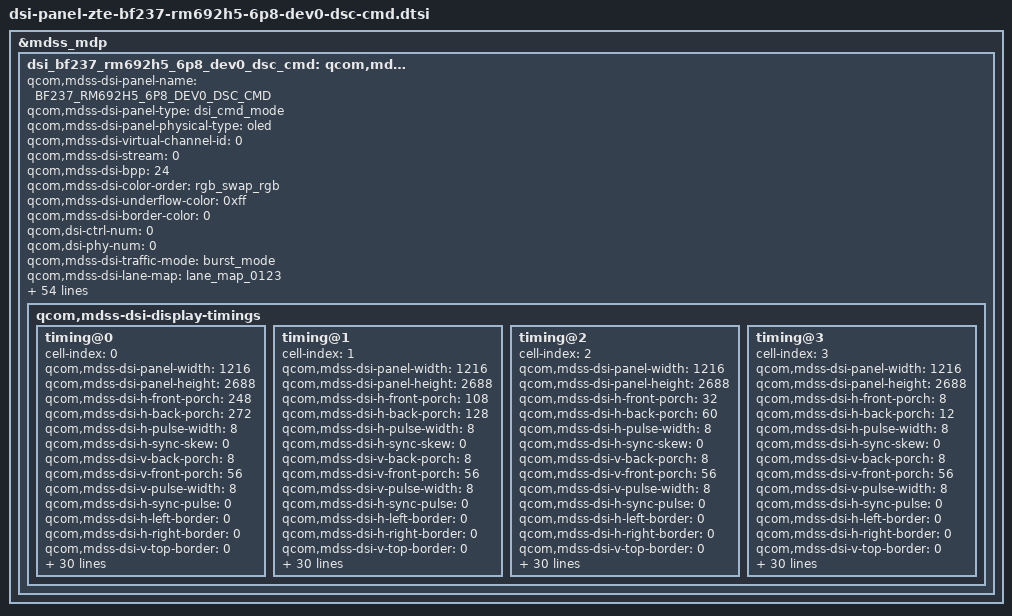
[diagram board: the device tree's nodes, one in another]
// SPDX-License-Identifier: BSD-3-Clause
/*
 * Copyright (c) 2023-2024 Qualcomm Innovation Center, Inc. All rights reserved.
 */

&mdss_mdp {
	dsi_bf237_rm692h5_6p8_dev0_dsc_cmd: qcom,mdss_dsi_bf237_rm692h5_6p8_dev0_dsc_cmd {
		qcom,mdss-dsi-panel-name =
				"BF237_RM692H5_6P8_DEV0_DSC_CMD";
		qcom,mdss-dsi-panel-type = "dsi_cmd_mode";
		qcom,mdss-dsi-panel-physical-type = "oled";
		qcom,mdss-dsi-virtual-channel-id = <0>;
		qcom,mdss-dsi-stream = <0>;
		qcom,mdss-dsi-bpp = <24>;
		qcom,mdss-dsi-color-order = "rgb_swap_rgb";
		qcom,mdss-dsi-underflow-color = <0xff>;
		qcom,mdss-dsi-border-color = <0>;
		qcom,dsi-ctrl-num = <0>;
		qcom,dsi-phy-num = <0>;
		qcom,mdss-dsi-traffic-mode = "burst_mode";
		qcom,mdss-dsi-lane-map = "lane_map_0123";
		qcom,mdss-dsi-bllp-eof-power-mode;
		qcom,mdss-dsi-bllp-power-mode;
		qcom,mdss-dsi-lane-0-state;
		qcom,mdss-dsi-lane-1-state;
		qcom,mdss-dsi-lane-2-state;
		qcom,mdss-dsi-lane-3-state;
		qcom,mdss-dsi-lp11-init;
		qcom,mdss-dsi-tx-eot-append;
		qcom,mdss-dsi-dma-trigger = "trigger_sw";
		qcom,mdss-dsi-mdp-trigger = "none";
		qcom,mdss-dsi-reset-sequence = <1 10>, <0 10>, <1 40>;
		qcom,mdss-dsi-te-pin-select = <1>;
		qcom,mdss-dsi-te-dcs-command = <1>;
		qcom,mdss-dsi-te-check-enable;
		qcom,mdss-dsi-te-using-te-pin;
		qcom,mdss-dsi-bl-min-level = <1>;
		qcom,mdss-dsi-bl-max-level = <4095>;
		qcom,mdss-dsi-bl-pmic-control-type = "bl_ctrl_dcs";
		qcom,mdss-dsi-panel-hdr-enabled;
		qcom,mdss-dsi-panel-hdr-color-primaries = <14500 15500 34015
			15980 13030 34670 6950 2565>;
		qcom,mdss-dsi-panel-peak-brightness = <6680000>;
		qcom,mdss-dsi-panel-blackness-level = <20>;
		qcom,mdss-pan-physical-width-dimension = <72>;
		qcom,mdss-pan-physical-height-dimension = <158>;
		qcom,bl-dcs-cmd-state = "dsi_lp_mode";
		qcom,bl-dsc-cmd-state = "dsi_lp_mode";
		qcom,mdss-disable-cesta-hw-sleep;
		qcom,mdss-dsi-display-timings {
			timing@0 {
				cell-index = <0>;
				qcom,mdss-dsi-panel-width = <1216>;
				qcom,mdss-dsi-panel-height = <2688>;
				qcom,mdss-dsi-h-front-porch = <248>;
				qcom,mdss-dsi-h-back-porch = <272>;
				qcom,mdss-dsi-h-pulse-width = <8>;
				qcom,mdss-dsi-h-sync-skew = <0>;
				qcom,mdss-dsi-v-back-porch = <8>;
				qcom,mdss-dsi-v-front-porch = <56>;
				qcom,mdss-dsi-v-pulse-width = <8>;
				qcom,mdss-dsi-h-sync-pulse = <0>;
				qcom,mdss-dsi-h-left-border = <0>;
				qcom,mdss-dsi-h-right-border = <0>;
				qcom,mdss-dsi-v-top-border = <0>;
				qcom,mdss-dsi-v-bottom-border = <0>;
				qcom,mdss-dsi-panel-framerate = <60>;
				qcom,mdss-mdp-transfer-time-us = <6235>;
				/*qcom,mdss-dsi-panel-clockrate = <1060499680>;*/
				/*qcom,mdss-dsi-panel-clockrate = <1059430000>; 60HZ*/

				qcom,mdss-dsi-on-command = [
					/* ESD RECOVER */
					15 01 00 00 00 00 02 FE D4
					15 01 00 00 00 00 02 40 03
					15 01 00 00 00 00 02 FE FD
					15 01 00 00 00 00 02 80 06
					15 01 00 00 00 00 02 83 00
					15 01 00 00 00 00 02 EE 00
					15 01 00 00 00 00 02 EF 00
					15 01 00 00 00 00 02 FE D0
					15 01 00 00 00 00 02 7E 80
					15 01 00 00 00 00 02 FE B6
					15 01 00 00 00 00 02 01 74
					15 01 00 00 00 00 02 FE A1
					15 01 00 00 00 00 02 74 72
					15 01 00 00 00 00 02 C3 C3
					15 01 00 00 00 00 02 C4 FF
					15 01 00 00 00 00 02 C5 7F
/*10bit 3.75 begin*/
15 01 00 00 00 00 02 FE 00
15 01 00 00 00 00 02 FA 01
15 01 00 00 00 00 02 FE D2
15 01 00 00 00 00 02 97 08
15 01 00 00 00 00 02 36 11
15 01 00 00 00 00 02 39 ab
15 01 00 00 00 00 02 3A 30
15 01 00 00 00 00 02 3B 80
15 01 00 00 00 00 02 3D 0a
15 01 00 00 00 00 02 3F 80
15 01 00 00 00 00 02 40 04
15 01 00 00 00 00 02 41 c0
15 01 00 00 00 00 02 42 00
15 01 00 00 00 00 02 43 10
15 01 00 00 00 00 02 44 02
15 01 00 00 00 00 02 45 60
15 01 00 00 00 00 02 46 02
15 01 00 00 00 00 02 47 60
15 01 00 00 00 00 02 48 02
15 01 00 00 00 00 02 49 00
15 01 00 00 00 00 02 4A 02
15 01 00 00 00 00 02 4B 31
15 01 00 00 00 00 02 4D 20
15 01 00 00 00 00 02 4E 01
15 01 00 00 00 00 02 4F 68
15 01 00 00 00 00 02 50 00
15 01 00 00 00 00 02 51 08
15 01 00 00 00 00 02 53 0c
15 01 00 00 00 00 02 54 06
15 01 00 00 00 00 02 55 67
15 01 00 00 00 00 02 56 05
15 01 00 00 00 00 02 58 ad
15 01 00 00 00 00 02 59 18
15 01 00 00 00 00 02 5A 00
15 01 00 00 00 00 02 5B 11
15 01 00 00 00 00 02 5C 00
15 01 00 00 00 00 02 5D 07
15 01 00 00 00 00 02 5E 10
15 01 00 00 00 00 02 5F 20
15 01 00 00 00 00 02 60 00
15 01 00 00 00 00 02 61 06
15 01 00 00 00 00 02 62 0f
15 01 00 00 00 00 02 63 0f
15 01 00 00 00 00 02 64 33
15 01 00 00 00 00 02 65 0e
15 01 00 00 00 00 02 66 1c
15 01 00 00 00 00 02 67 2a
15 01 00 00 00 00 02 68 38
15 01 00 00 00 00 02 69 46
15 01 00 00 00 00 02 6A 54
15 01 00 00 00 00 02 6B 62
15 01 00 00 00 00 02 6C 69
15 01 00 00 00 00 02 6D 70
15 01 00 00 00 00 02 6E 77
15 01 00 00 00 00 02 6F 79
15 01 00 00 00 00 02 70 7b
15 01 00 00 00 00 02 71 7d
15 01 00 00 00 00 02 72 7e
15 01 00 00 00 00 02 73 02
15 01 00 00 00 00 02 74 02
15 01 00 00 00 00 02 75 22
15 01 00 00 00 00 02 76 00
15 01 00 00 00 00 02 77 2a
15 01 00 00 00 00 02 78 40
15 01 00 00 00 00 02 79 2a
15 01 00 00 00 00 02 7A be
15 01 00 00 00 00 02 7B 3a
15 01 00 00 00 00 02 7C fc
15 01 00 00 00 00 02 7D 3a
15 01 00 00 00 00 02 7E fa
15 01 00 00 00 00 02 7F 3a
15 01 00 00 00 00 02 80 f8
15 01 00 00 00 00 02 81 3b
15 01 00 00 00 00 02 82 38
15 01 00 00 00 00 02 83 3b
15 01 00 00 00 00 02 84 78
15 01 00 00 00 00 02 85 3b
15 01 00 00 00 00 02 86 b6
15 01 00 00 00 00 02 87 4b
15 01 00 00 00 00 02 88 f6
15 01 00 00 00 00 02 89 4c
15 01 00 00 00 00 02 8A 34
15 01 00 00 00 00 02 8B 4c
15 01 00 00 00 00 02 8C 74
15 01 00 00 00 00 02 8D 5c
15 01 00 00 00 00 02 8E 74
15 01 00 00 00 00 02 8F 8c
15 01 00 00 00 00 02 90 f4
15 01 00 00 00 00 02 91 00
15 01 00 00 00 00 02 92 00
15 01 00 00 00 00 02 93 00
15 01 00 00 00 00 02 94 00
15 01 00 00 00 00 02 95 00
15 01 00 00 00 00 02 96 00
/*10bit 3.75 end*/

/*acl function*/
15 01 00 00 00 00 02 FE 34
15 01 00 00 00 00 02 82 C0
15 01 00 00 00 00 02 83 04
15 01 00 00 00 00 02 00 08
15 01 00 00 00 00 02 1C 00
15 01 00 00 00 00 02 1D 10
15 01 00 00 00 00 02 49 05
15 01 00 00 00 00 02 1E 00
15 01 00 00 00 00 02 1F 00
15 01 00 00 00 00 02 20 00
15 01 00 00 00 00 02 21 70
15 01 00 00 00 00 02 22 00
15 01 00 00 00 00 02 23 F8
15 01 00 00 00 00 02 24 77
15 01 00 00 00 00 02 25 F8
15 01 00 00 00 00 02 26 F8
15 01 00 00 00 00 02 2F 00
15 01 00 00 00 00 02 30 00
15 01 00 00 00 00 02 31 00
15 01 00 00 00 00 02 32 00
15 01 00 00 00 00 02 33 00
15 01 00 00 00 00 02 34 00
15 01 00 00 00 00 02 35 00
15 01 00 00 00 00 02 36 C4
15 01 00 00 00 00 02 37 00
15 01 00 00 00 00 02 38 87
15 01 00 00 00 00 02 39 00
15 01 00 00 00 00 02 3A 4B
15 01 00 00 00 00 02 3B 00
15 01 00 00 00 00 02 3D 00
15 01 00 00 00 00 02 3F 00
15 01 00 00 00 00 02 40 00
15 01 00 00 00 00 02 41 00
15 01 00 00 00 00 02 42 00
15 01 00 00 00 00 02 54 03
15 01 00 00 00 00 02 55 77
15 01 00 00 00 00 02 56 F8
15 01 00 00 00 00 02 58 F8
15 01 00 00 00 00 02 59 77
15 01 00 00 00 00 02 5A F8
15 01 00 00 00 00 02 5B F8
15 01 00 00 00 00 02 5C 77
15 01 00 00 00 00 02 5D F8
15 01 00 00 00 00 02 5E F8
15 01 00 00 00 00 02 5F 77
15 01 00 00 00 00 02 60 F8
15 01 00 00 00 00 02 61 F8
15 01 00 00 00 00 02 62 77
15 01 00 00 00 00 02 63 F8
15 01 00 00 00 00 02 64 F8
15 01 00 00 00 00 02 65 77
15 01 00 00 00 00 02 66 F8
15 01 00 00 00 00 02 67 F8
15 01 00 00 00 00 02 77 07
15 01 00 00 00 00 02 78 F8
/*FDC effect*/
15 01 00 00 00 00 02 FE 00
15 01 00 00 00 00 02 2F 07
15 01 00 00 00 00 02 FE 5A
15 01 00 00 00 00 02 4A 1A
15 01 00 00 00 00 02 4B 00
15 01 00 00 00 00 02 52 00
15 01 00 00 00 00 02 53 08
15 01 00 00 00 00 02 55 00
15 01 00 00 00 00 02 5E 00
15 01 00 00 00 00 02 60 04
15 01 00 00 00 00 02 61 04
15 01 00 00 00 00 02 66 00
15 01 00 00 00 00 02 69 00
15 01 00 00 00 00 02 6E 00
15 01 00 00 00 00 02 70 00
15 01 00 00 00 00 02 76 00
15 01 00 00 00 00 02 78 00
15 01 00 00 00 00 02 7E 00
15 01 00 00 00 00 02 86 00
15 01 00 00 00 00 02 91 10
15 01 00 00 00 00 02 92 00
15 01 00 00 00 00 02 93 10
15 01 00 00 00 00 02 94 06
15 01 00 00 00 00 02 98 00
15 01 00 00 00 00 02 99 00
15 01 00 00 00 00 02 9B 00
15 01 00 00 00 00 02 9C 00
15 01 00 00 00 00 02 A2 00
15 01 00 00 00 00 02 A7 00
15 01 00 00 00 00 02 AA 00
15 01 00 00 00 00 02 AB 00
15 01 00 00 00 00 02 B0 00
15 01 00 00 00 00 02 B3 00
15 01 00 00 00 00 02 B8 00
15 01 00 00 00 00 02 BA 00
15 01 00 00 00 00 02 C0 00
15 01 00 00 00 00 02 C8 00
15 01 00 00 00 00 02 D0 00
15 01 00 00 00 00 02 DB 30
15 01 00 00 00 00 02 DC 3D
15 01 00 00 00 00 02 DD 20
15 01 00 00 00 00 02 DE 00
15 01 00 00 00 00 02 E2 30
15 01 00 00 00 00 02 E3 30
15 01 00 00 00 00 02 E4 20
15 01 00 00 00 00 02 E5 00
15 01 00 00 00 00 02 E6 00
15 01 00 00 00 00 02 EA 10
15 01 00 00 00 00 02 EB 1A
15 01 00 00 00 00 02 F0 00
15 01 00 00 00 00 02 F3 0D
15 01 00 00 00 00 02 F4 02
15 01 00 00 00 00 02 F9 00
15 01 00 00 00 00 02 FE 5B
15 01 00 00 00 00 02 01 0D
15 01 00 00 00 00 02 02 0A
15 01 00 00 00 00 02 07 00
15 01 00 00 00 00 02 09 06
15 01 00 00 00 00 02 0F 00
15 01 00 00 00 00 02 11 06
15 01 00 00 00 00 02 19 00
15 01 00 00 00 00 02 36 00
15 01 00 00 00 00 02 37 00
15 01 00 00 00 00 02 3F 00
15 01 00 00 00 00 02 45 F9
15 01 00 00 00 00 02 46 00
15 01 00 00 00 00 02 47 00
15 01 00 00 00 00 02 4D F9
15 01 00 00 00 00 02 55 FB
15 01 00 00 00 00 02 56 FF
15 01 00 00 00 00 02 5E FC
					/* init code */
					15 01 00 00 00 00 02 FE 00
					15 01 00 00 00 00 02 C2 08
					15 01 00 00 00 00 02 35 00
					15 01 00 00 00 00 02 53 20
					39 01 00 00 00 00 03 51 00 00
					05 01 00 00 64 00 01 11
					05 01 00 00 14 00 01 29
					];
				qcom,mdss-dsi-off-command = [
					15 01 00 00 14 00 02 FE 00
					05 01 00 00 10 00 01 28
					05 01 00 00 78 00 01 10
				];
				qcom,mdss-dsi-on-command-state = "dsi_lp_mode";
				qcom,mdss-dsi-off-command-state = "dsi_lp_mode";

				qcom,mdss-dsi-lp1-command = [
					15 01 00 00 00 00 02 FE 00
					05 01 00 00 14 00 01 39
				];
				qcom,mdss-dsi-lp1-command-state =
					"dsi_lp_mode";
				qcom,mdss-dsi-nolp-command = [
					15 01 00 00 00 00 02 FE 00
					39 01 00 00 00 00 03 51 00 00
					05 01 00 00 00 00 01 38
				];
				qcom,mdss-dsi-nolp-command-state =
					"dsi_lp_mode";
				qcom,mdss-dsi-timing-switch-command = [
39 00 00 40 00 00 02 FE 00
39 00 00 40 00 00 02 2F 07

39 00 00 40 00 00 02 FE 5A
39 00 00 40 00 00 02 4A 1A
39 00 00 40 00 00 02 4B 00
39 00 00 40 00 00 02 52 00
39 00 00 40 00 00 02 53 08
39 00 00 40 00 00 02 55 00
39 00 00 40 00 00 02 5E 00
39 00 00 40 00 00 02 60 04
39 00 00 40 00 00 02 61 04
39 00 00 40 00 00 02 66 00
39 00 00 40 00 00 02 69 00
39 00 00 40 00 00 02 6E 00
39 00 00 40 00 00 02 70 00
39 00 00 40 00 00 02 76 00
39 00 00 40 00 00 02 78 00
39 00 00 40 00 00 02 7E 00
39 00 00 40 00 00 02 86 00
39 00 00 40 00 00 02 91 10
39 00 00 40 00 00 02 92 00
39 00 00 40 00 00 02 93 10
39 00 00 40 00 00 02 94 06
39 00 00 40 00 00 02 98 00
39 00 00 40 00 00 02 99 00
39 00 00 40 00 00 02 9B 00
39 00 00 40 00 00 02 9C 00
39 00 00 40 00 00 02 A2 00
39 00 00 40 00 00 02 A7 00
39 00 00 40 00 00 02 AA 00
39 00 00 40 00 00 02 AB 00
39 00 00 40 00 00 02 B0 00
39 00 00 40 00 00 02 B3 00
39 00 00 40 00 00 02 B8 00
39 00 00 40 00 00 02 BA 00
39 00 00 40 00 00 02 C0 00
39 00 00 40 00 00 02 C8 00
39 00 00 40 00 00 02 D0 00
39 00 00 40 00 00 02 DB 30
39 00 00 40 00 00 02 DC 3D
39 00 00 40 00 00 02 DD 20
39 00 00 40 00 00 02 DE 00
39 00 00 40 00 00 02 E2 30
39 00 00 40 00 00 02 E3 30
39 00 00 40 00 00 02 E4 20
39 00 00 40 00 00 02 E5 00
39 00 00 40 00 00 02 E6 00
39 00 00 40 00 00 02 EA 10
39 00 00 40 00 00 02 EB 1A
39 00 00 40 00 00 02 F0 00
39 00 00 40 00 00 02 F3 0D
39 00 00 40 00 00 02 F4 02
39 00 00 40 00 00 02 F9 00
39 00 00 40 00 00 02 FE 5B
39 00 00 40 00 00 02 01 0D
39 00 00 40 00 00 02 02 0A
39 00 00 40 00 00 02 07 00
39 00 00 40 00 00 02 09 06
39 00 00 40 00 00 02 0F 00
39 00 00 40 00 00 02 11 06
39 00 00 40 00 00 02 19 00
39 00 00 40 00 00 02 36 00
39 00 00 40 00 00 02 37 00
39 00 00 40 00 00 02 3F 00
39 00 00 40 00 00 02 45 F9
39 00 00 40 00 00 02 46 00
39 00 00 40 00 00 02 47 00
39 00 00 40 00 00 02 4D F9
39 00 00 40 00 00 02 55 FB
39 00 00 40 00 00 02 56 FF
39 00 00 40 00 00 02 5E FC
					39 00 00 00 00 00 02 FE 00
				];
				qcom,mdss-dsi-timing-switch-command-state =
				"dsi_lp_mode";
				qcom,compression-mode = "dsc";
				qcom,mdss-dsc-slice-height = <16>;
				qcom,mdss-dsc-slice-width = <608>;
				qcom,mdss-dsc-slice-per-pkt = <2>;
				qcom,mdss-dsc-bit-per-component = <10>;
				qcom,mdss-dsc-bit-per-pixel = <8>;
				qcom,mdss-dsc-block-prediction-enable;
			};
			timing@1{
				cell-index = <1>;
				qcom,mdss-dsi-panel-width = <1216>;
				qcom,mdss-dsi-panel-height = <2688>;
				qcom,mdss-dsi-h-front-porch = <108>;
				qcom,mdss-dsi-h-back-porch = <128>;
				qcom,mdss-dsi-h-pulse-width = <8>;
				qcom,mdss-dsi-h-sync-skew = <0>;
				qcom,mdss-dsi-v-back-porch = <8>;
				qcom,mdss-dsi-v-front-porch = <56>;
				qcom,mdss-dsi-v-pulse-width = <8>;
				qcom,mdss-dsi-h-sync-pulse = <0>;
				qcom,mdss-dsi-h-left-border = <0>;
				qcom,mdss-dsi-h-right-border = <0>;
				qcom,mdss-dsi-v-top-border = <0>;
				qcom,mdss-dsi-v-bottom-border = <0>;
				qcom,mdss-dsi-panel-framerate = <90>;
				qcom,mdss-mdp-transfer-time-us = <6235>;
				/*qcom,mdss-dsi-panel-clockrate = <1060531504>;*/
				/*qcom,mdss-dsi-panel-clockrate = <1060050000>; 90HZ*/

				qcom,mdss-dsi-on-command = [
					/* ESD RECOVER */
					15 01 00 00 00 00 02 FE D4
					15 01 00 00 00 00 02 40 03
					15 01 00 00 00 00 02 FE FD
					15 01 00 00 00 00 02 80 06
					15 01 00 00 00 00 02 83 00
					15 01 00 00 00 00 02 EE 00
					15 01 00 00 00 00 02 EF 00
					15 01 00 00 00 00 02 FE D0
					15 01 00 00 00 00 02 7E 80
					15 01 00 00 00 00 02 FE B6
					15 01 00 00 00 00 02 01 74
					15 01 00 00 00 00 02 FE A1
					15 01 00 00 00 00 02 74 72
					15 01 00 00 00 00 02 C3 C3
					15 01 00 00 00 00 02 C4 FF
					15 01 00 00 00 00 02 C5 7F
/*10bit 3.75 begin*/
15 01 00 00 00 00 02 FE 00
15 01 00 00 00 00 02 FA 01
15 01 00 00 00 00 02 FE D2
15 01 00 00 00 00 02 97 08
15 01 00 00 00 00 02 36 11
15 01 00 00 00 00 02 39 ab
15 01 00 00 00 00 02 3A 30
15 01 00 00 00 00 02 3B 80
15 01 00 00 00 00 02 3D 0a
15 01 00 00 00 00 02 3F 80
15 01 00 00 00 00 02 40 04
15 01 00 00 00 00 02 41 c0
15 01 00 00 00 00 02 42 00
15 01 00 00 00 00 02 43 10
15 01 00 00 00 00 02 44 02
15 01 00 00 00 00 02 45 60
15 01 00 00 00 00 02 46 02
15 01 00 00 00 00 02 47 60
15 01 00 00 00 00 02 48 02
15 01 00 00 00 00 02 49 00
15 01 00 00 00 00 02 4A 02
15 01 00 00 00 00 02 4B 31
15 01 00 00 00 00 02 4D 20
15 01 00 00 00 00 02 4E 01
15 01 00 00 00 00 02 4F 68
15 01 00 00 00 00 02 50 00
15 01 00 00 00 00 02 51 08
15 01 00 00 00 00 02 53 0c
15 01 00 00 00 00 02 54 06
15 01 00 00 00 00 02 55 67
15 01 00 00 00 00 02 56 05
15 01 00 00 00 00 02 58 ad
15 01 00 00 00 00 02 59 18
15 01 00 00 00 00 02 5A 00
15 01 00 00 00 00 02 5B 11
15 01 00 00 00 00 02 5C 00
15 01 00 00 00 00 02 5D 07
15 01 00 00 00 00 02 5E 10
15 01 00 00 00 00 02 5F 20
15 01 00 00 00 00 02 60 00
15 01 00 00 00 00 02 61 06
15 01 00 00 00 00 02 62 0f
15 01 00 00 00 00 02 63 0f
15 01 00 00 00 00 02 64 33
15 01 00 00 00 00 02 65 0e
15 01 00 00 00 00 02 66 1c
15 01 00 00 00 00 02 67 2a
15 01 00 00 00 00 02 68 38
15 01 00 00 00 00 02 69 46
15 01 00 00 00 00 02 6A 54
15 01 00 00 00 00 02 6B 62
15 01 00 00 00 00 02 6C 69
15 01 00 00 00 00 02 6D 70
15 01 00 00 00 00 02 6E 77
15 01 00 00 00 00 02 6F 79
15 01 00 00 00 00 02 70 7b
15 01 00 00 00 00 02 71 7d
15 01 00 00 00 00 02 72 7e
15 01 00 00 00 00 02 73 02
15 01 00 00 00 00 02 74 02
15 01 00 00 00 00 02 75 22
15 01 00 00 00 00 02 76 00
15 01 00 00 00 00 02 77 2a
15 01 00 00 00 00 02 78 40
15 01 00 00 00 00 02 79 2a
15 01 00 00 00 00 02 7A be
15 01 00 00 00 00 02 7B 3a
15 01 00 00 00 00 02 7C fc
15 01 00 00 00 00 02 7D 3a
15 01 00 00 00 00 02 7E fa
15 01 00 00 00 00 02 7F 3a
15 01 00 00 00 00 02 80 f8
15 01 00 00 00 00 02 81 3b
15 01 00 00 00 00 02 82 38
15 01 00 00 00 00 02 83 3b
15 01 00 00 00 00 02 84 78
15 01 00 00 00 00 02 85 3b
15 01 00 00 00 00 02 86 b6
15 01 00 00 00 00 02 87 4b
15 01 00 00 00 00 02 88 f6
15 01 00 00 00 00 02 89 4c
15 01 00 00 00 00 02 8A 34
15 01 00 00 00 00 02 8B 4c
15 01 00 00 00 00 02 8C 74
15 01 00 00 00 00 02 8D 5c
15 01 00 00 00 00 02 8E 74
15 01 00 00 00 00 02 8F 8c
15 01 00 00 00 00 02 90 f4
15 01 00 00 00 00 02 91 00
15 01 00 00 00 00 02 92 00
15 01 00 00 00 00 02 93 00
15 01 00 00 00 00 02 94 00
15 01 00 00 00 00 02 95 00
15 01 00 00 00 00 02 96 00
/*10bit 3.75 end*/
/*acl function*/
15 01 00 00 00 00 02 FE 34
15 01 00 00 00 00 02 82 C0
15 01 00 00 00 00 02 83 04
15 01 00 00 00 00 02 00 08
15 01 00 00 00 00 02 1C 00
15 01 00 00 00 00 02 1D 10
15 01 00 00 00 00 02 49 05
15 01 00 00 00 00 02 1E 00
15 01 00 00 00 00 02 1F 00
15 01 00 00 00 00 02 20 00
15 01 00 00 00 00 02 21 70
15 01 00 00 00 00 02 22 00
15 01 00 00 00 00 02 23 F8
15 01 00 00 00 00 02 24 77
15 01 00 00 00 00 02 25 F8
15 01 00 00 00 00 02 26 F8
15 01 00 00 00 00 02 2F 00
15 01 00 00 00 00 02 30 00
15 01 00 00 00 00 02 31 00
15 01 00 00 00 00 02 32 00
15 01 00 00 00 00 02 33 00
15 01 00 00 00 00 02 34 00
15 01 00 00 00 00 02 35 00
15 01 00 00 00 00 02 36 C4
15 01 00 00 00 00 02 37 00
15 01 00 00 00 00 02 38 87
15 01 00 00 00 00 02 39 00
15 01 00 00 00 00 02 3A 4B
15 01 00 00 00 00 02 3B 00
15 01 00 00 00 00 02 3D 00
15 01 00 00 00 00 02 3F 00
15 01 00 00 00 00 02 40 00
15 01 00 00 00 00 02 41 00
15 01 00 00 00 00 02 42 00
15 01 00 00 00 00 02 54 03
15 01 00 00 00 00 02 55 77
15 01 00 00 00 00 02 56 F8
15 01 00 00 00 00 02 58 F8
15 01 00 00 00 00 02 59 77
15 01 00 00 00 00 02 5A F8
15 01 00 00 00 00 02 5B F8
15 01 00 00 00 00 02 5C 77
15 01 00 00 00 00 02 5D F8
15 01 00 00 00 00 02 5E F8
15 01 00 00 00 00 02 5F 77
15 01 00 00 00 00 02 60 F8
15 01 00 00 00 00 02 61 F8
15 01 00 00 00 00 02 62 77
15 01 00 00 00 00 02 63 F8
15 01 00 00 00 00 02 64 F8
15 01 00 00 00 00 02 65 77
15 01 00 00 00 00 02 66 F8
15 01 00 00 00 00 02 67 F8
15 01 00 00 00 00 02 77 07
15 01 00 00 00 00 02 78 F8
/* FDC */
15 01 00 00 00 00 02 FE 00
15 01 00 00 00 00 02 2F 06
15 01 00 00 00 00 02 FE 5A
15 01 00 00 00 00 02 4A 00
15 01 00 00 00 00 02 4B 00
15 01 00 00 00 00 02 52 00
15 01 00 00 00 00 02 53 00
15 01 00 00 00 00 02 55 00
15 01 00 00 00 00 02 60 00
15 01 00 00 00 00 02 61 00
15 01 00 00 00 00 02 66 00
15 01 00 00 00 00 02 6E 00
15 01 00 00 00 00 02 70 00
15 01 00 00 00 00 02 76 00
15 01 00 00 00 00 02 7E 00
15 01 00 00 00 00 02 86 00
15 01 00 00 00 00 02 91 12
15 01 00 00 00 00 02 92 0A
15 01 00 00 00 00 02 93 00
15 01 00 00 00 00 02 94 00
15 01 00 00 00 00 02 98 10
15 01 00 00 00 00 02 99 06
15 01 00 00 00 00 02 9B 00
15 01 00 00 00 00 02 9C 00
15 01 00 00 00 00 02 AB 00
15 01 00 00 00 00 02 B0 00
15 01 00 00 00 00 02 B8 00
15 01 00 00 00 00 02 BA 00
15 01 00 00 00 00 02 C0 00
15 01 00 00 00 00 02 C8 00
15 01 00 00 00 00 02 D0 00
15 01 00 00 00 00 02 DB 66
15 01 00 00 00 00 02 DC 5A
15 01 00 00 00 00 02 DD 26
15 01 00 00 00 00 02 DE 00
15 01 00 00 00 00 02 E2 55
15 01 00 00 00 00 02 E3 2E
15 01 00 00 00 00 02 E4 36
15 01 00 00 00 00 02 E5 00
15 01 00 00 00 00 02 E6 00
15 01 00 00 00 00 02 EA 20
15 01 00 00 00 00 02 EB 14
15 01 00 00 00 00 02 F3 15
15 01 00 00 00 00 02 F4 12
15 01 00 00 00 00 02 F9 00
15 01 00 00 00 00 02 FE 5B
15 01 00 00 00 00 02 01 12
15 01 00 00 00 00 02 02 12
15 01 00 00 00 00 02 07 00
15 01 00 00 00 00 02 09 08
15 01 00 00 00 00 02 0F 00
15 01 00 00 00 00 02 11 0A
15 01 00 00 00 00 02 19 06
15 01 00 00 00 00 02 36 10
15 01 00 00 00 00 02 37 00
15 01 00 00 00 00 02 3F 00
15 01 00 00 00 00 02 45 FE
15 01 00 00 00 00 02 46 00
15 01 00 00 00 00 02 47 00
15 01 00 00 00 00 02 4D FA
15 01 00 00 00 00 02 55 00
15 01 00 00 00 00 02 56 00
15 01 00 00 00 00 02 5E 00
					/* init code */
					15 01 00 00 00 00 02 FE 00
					15 01 00 00 00 00 02 C2 08
					15 01 00 00 00 00 02 35 00
					15 01 00 00 00 00 02 53 20
					39 01 00 00 00 00 03 51 00 00
					05 01 00 00 64 00 01 11
					05 01 00 00 14 00 01 29
					];
				qcom,mdss-dsi-off-command = [
					15 01 00 00 14 00 02 FE 00
					05 01 00 00 10 00 01 28
					05 01 00 00 78 00 01 10
				];
				qcom,mdss-dsi-on-command-state = "dsi_lp_mode";
				qcom,mdss-dsi-off-command-state = "dsi_lp_mode";

				qcom,mdss-dsi-lp1-command = [
					15 01 00 00 00 00 02 FE 00
					05 01 00 00 14 00 01 39
				];
				qcom,mdss-dsi-lp1-command-state =
					"dsi_lp_mode";
				qcom,mdss-dsi-nolp-command = [
					15 01 00 00 00 00 02 FE 00
					39 01 00 00 00 00 03 51 00 00
					05 01 00 00 00 00 01 38
				];
				qcom,mdss-dsi-nolp-command-state =
					"dsi_lp_mode";
				qcom,mdss-dsi-timing-switch-command = [
39 00 00 40 00 00 02 FE 00
39 00 00 40 00 00 02 2F 06

39 00 00 40 00 00 02 FE 5A
39 00 00 40 00 00 02 4A 00
39 00 00 40 00 00 02 4B 00
39 00 00 40 00 00 02 52 00
39 00 00 40 00 00 02 53 00
39 00 00 40 00 00 02 55 00
39 00 00 40 00 00 02 60 00
39 00 00 40 00 00 02 61 00
39 00 00 40 00 00 02 66 00
39 00 00 40 00 00 02 6E 00
39 00 00 40 00 00 02 70 00
39 00 00 40 00 00 02 76 00
39 00 00 40 00 00 02 7E 00
39 00 00 40 00 00 02 86 00
39 00 00 40 00 00 02 91 12
39 00 00 40 00 00 02 92 0A
39 00 00 40 00 00 02 93 00
39 00 00 40 00 00 02 94 00
39 00 00 40 00 00 02 98 10
39 00 00 40 00 00 02 99 06
39 00 00 40 00 00 02 9B 00
39 00 00 40 00 00 02 9C 00
39 00 00 40 00 00 02 AB 00
39 00 00 40 00 00 02 B0 00
39 00 00 40 00 00 02 B8 00
39 00 00 40 00 00 02 BA 00
39 00 00 40 00 00 02 C0 00
39 00 00 40 00 00 02 C8 00
39 00 00 40 00 00 02 D0 00
39 00 00 40 00 00 02 DB 66
39 00 00 40 00 00 02 DC 5A
39 00 00 40 00 00 02 DD 26
39 00 00 40 00 00 02 DE 00
39 00 00 40 00 00 02 E2 55
39 00 00 40 00 00 02 E3 2E
39 00 00 40 00 00 02 E4 36
39 00 00 40 00 00 02 E5 00
39 00 00 40 00 00 02 E6 00
39 00 00 40 00 00 02 EA 20
39 00 00 40 00 00 02 EB 14
39 00 00 40 00 00 02 F3 15
39 00 00 40 00 00 02 F4 12
39 00 00 40 00 00 02 F9 00
39 00 00 40 00 00 02 FE 5B
39 00 00 40 00 00 02 01 12
39 00 00 40 00 00 02 02 12
39 00 00 40 00 00 02 07 00
39 00 00 40 00 00 02 09 08
39 00 00 40 00 00 02 0F 00
39 00 00 40 00 00 02 11 0A
39 00 00 40 00 00 02 19 06
39 00 00 40 00 00 02 36 10
39 00 00 40 00 00 02 37 00
39 00 00 40 00 00 02 3F 00
39 00 00 40 00 00 02 45 FE
39 00 00 40 00 00 02 46 00
39 00 00 40 00 00 02 47 00
39 00 00 40 00 00 02 4D FA
39 00 00 40 00 00 02 55 00
39 00 00 40 00 00 02 56 00
39 00 00 40 00 00 02 5E 00
					39 00 00 00 00 00 02 FE 00
				];
				qcom,mdss-dsi-timing-switch-command-state =
				"dsi_lp_mode";
				qcom,compression-mode = "dsc";
				qcom,mdss-dsc-slice-height = <16>;
				qcom,mdss-dsc-slice-width = <608>;
				qcom,mdss-dsc-slice-per-pkt = <2>;
				qcom,mdss-dsc-bit-per-component = <10>;
				qcom,mdss-dsc-bit-per-pixel = <8>;
				qcom,mdss-dsc-block-prediction-enable;
			};
			timing@2{
				cell-index = <2>;
				qcom,mdss-dsi-panel-width = <1216>;
				qcom,mdss-dsi-panel-height = <2688>;
				qcom,mdss-dsi-h-front-porch = <32>;
				qcom,mdss-dsi-h-back-porch = <60>;
				qcom,mdss-dsi-h-pulse-width = <8>;
				qcom,mdss-dsi-h-sync-skew = <0>;
				qcom,mdss-dsi-v-back-porch = <8>;
				qcom,mdss-dsi-v-front-porch = <56>;
				qcom,mdss-dsi-v-pulse-width = <8>;
				qcom,mdss-dsi-h-sync-pulse = <0>;
				qcom,mdss-dsi-h-left-border = <0>;
				qcom,mdss-dsi-h-right-border = <0>;
				qcom,mdss-dsi-v-top-border = <0>;
				qcom,mdss-dsi-v-bottom-border = <0>;
				qcom,mdss-dsi-panel-framerate = <120>;
				qcom,mdss-mdp-transfer-time-us = <6235>;
				/*qcom,mdss-dsi-panel-clockrate = <1060499680>;*/
				/*qcom,mdss-dsi-panel-clockrate = <1055700000>; 120HZ*/

				qcom,mdss-dsi-on-command = [
					/* ESD RECOVER */
					15 01 00 00 00 00 02 FE D4
					15 01 00 00 00 00 02 40 03
					15 01 00 00 00 00 02 FE FD
					15 01 00 00 00 00 02 80 06
					15 01 00 00 00 00 02 83 00
					15 01 00 00 00 00 02 EE 00
					15 01 00 00 00 00 02 EF 00
					15 01 00 00 00 00 02 FE D0
					15 01 00 00 00 00 02 7E 80
					15 01 00 00 00 00 02 FE B6
					15 01 00 00 00 00 02 01 74
					15 01 00 00 00 00 02 FE A1
					15 01 00 00 00 00 02 74 72
					15 01 00 00 00 00 02 C3 C3
					15 01 00 00 00 00 02 C4 FF
					15 01 00 00 00 00 02 C5 7F
/*10bit 3.75 begin*/
15 01 00 00 00 00 02 FE 00
15 01 00 00 00 00 02 FA 01
15 01 00 00 00 00 02 FE D2
15 01 00 00 00 00 02 97 08
15 01 00 00 00 00 02 36 11
15 01 00 00 00 00 02 39 ab
15 01 00 00 00 00 02 3A 30
15 01 00 00 00 00 02 3B 80
15 01 00 00 00 00 02 3D 0a
15 01 00 00 00 00 02 3F 80
15 01 00 00 00 00 02 40 04
15 01 00 00 00 00 02 41 c0
15 01 00 00 00 00 02 42 00
15 01 00 00 00 00 02 43 10
15 01 00 00 00 00 02 44 02
15 01 00 00 00 00 02 45 60
15 01 00 00 00 00 02 46 02
15 01 00 00 00 00 02 47 60
15 01 00 00 00 00 02 48 02
15 01 00 00 00 00 02 49 00
15 01 00 00 00 00 02 4A 02
15 01 00 00 00 00 02 4B 31
15 01 00 00 00 00 02 4D 20
15 01 00 00 00 00 02 4E 01
15 01 00 00 00 00 02 4F 68
15 01 00 00 00 00 02 50 00
15 01 00 00 00 00 02 51 08
15 01 00 00 00 00 02 53 0c
15 01 00 00 00 00 02 54 06
15 01 00 00 00 00 02 55 67
15 01 00 00 00 00 02 56 05
15 01 00 00 00 00 02 58 ad
15 01 00 00 00 00 02 59 18
15 01 00 00 00 00 02 5A 00
15 01 00 00 00 00 02 5B 11
15 01 00 00 00 00 02 5C 00
15 01 00 00 00 00 02 5D 07
15 01 00 00 00 00 02 5E 10
15 01 00 00 00 00 02 5F 20
15 01 00 00 00 00 02 60 00
15 01 00 00 00 00 02 61 06
15 01 00 00 00 00 02 62 0f
15 01 00 00 00 00 02 63 0f
15 01 00 00 00 00 02 64 33
15 01 00 00 00 00 02 65 0e
15 01 00 00 00 00 02 66 1c
15 01 00 00 00 00 02 67 2a
15 01 00 00 00 00 02 68 38
15 01 00 00 00 00 02 69 46
15 01 00 00 00 00 02 6A 54
15 01 00 00 00 00 02 6B 62
15 01 00 00 00 00 02 6C 69
15 01 00 00 00 00 02 6D 70
15 01 00 00 00 00 02 6E 77
15 01 00 00 00 00 02 6F 79
15 01 00 00 00 00 02 70 7b
15 01 00 00 00 00 02 71 7d
15 01 00 00 00 00 02 72 7e
15 01 00 00 00 00 02 73 02
15 01 00 00 00 00 02 74 02
15 01 00 00 00 00 02 75 22
15 01 00 00 00 00 02 76 00
15 01 00 00 00 00 02 77 2a
15 01 00 00 00 00 02 78 40
15 01 00 00 00 00 02 79 2a
15 01 00 00 00 00 02 7A be
15 01 00 00 00 00 02 7B 3a
15 01 00 00 00 00 02 7C fc
15 01 00 00 00 00 02 7D 3a
15 01 00 00 00 00 02 7E fa
15 01 00 00 00 00 02 7F 3a
15 01 00 00 00 00 02 80 f8
15 01 00 00 00 00 02 81 3b
15 01 00 00 00 00 02 82 38
15 01 00 00 00 00 02 83 3b
15 01 00 00 00 00 02 84 78
15 01 00 00 00 00 02 85 3b
15 01 00 00 00 00 02 86 b6
15 01 00 00 00 00 02 87 4b
15 01 00 00 00 00 02 88 f6
15 01 00 00 00 00 02 89 4c
15 01 00 00 00 00 02 8A 34
15 01 00 00 00 00 02 8B 4c
15 01 00 00 00 00 02 8C 74
15 01 00 00 00 00 02 8D 5c
15 01 00 00 00 00 02 8E 74
15 01 00 00 00 00 02 8F 8c
15 01 00 00 00 00 02 90 f4
15 01 00 00 00 00 02 91 00
15 01 00 00 00 00 02 92 00
15 01 00 00 00 00 02 93 00
15 01 00 00 00 00 02 94 00
15 01 00 00 00 00 02 95 00
15 01 00 00 00 00 02 96 00
/*10bit 3.75 end*/
/*acl function*/
15 01 00 00 00 00 02 FE 34
15 01 00 00 00 00 02 82 C0
15 01 00 00 00 00 02 83 04
15 01 00 00 00 00 02 00 08
15 01 00 00 00 00 02 1C 00
15 01 00 00 00 00 02 1D 10
15 01 00 00 00 00 02 49 05
15 01 00 00 00 00 02 1E 00
15 01 00 00 00 00 02 1F 00
15 01 00 00 00 00 02 20 00
15 01 00 00 00 00 02 21 70
15 01 00 00 00 00 02 22 00
15 01 00 00 00 00 02 23 F8
15 01 00 00 00 00 02 24 77
15 01 00 00 00 00 02 25 F8
15 01 00 00 00 00 02 26 F8
15 01 00 00 00 00 02 2F 00
15 01 00 00 00 00 02 30 00
15 01 00 00 00 00 02 31 00
15 01 00 00 00 00 02 32 00
15 01 00 00 00 00 02 33 00
15 01 00 00 00 00 02 34 00
15 01 00 00 00 00 02 35 00
15 01 00 00 00 00 02 36 C4
15 01 00 00 00 00 02 37 00
15 01 00 00 00 00 02 38 87
15 01 00 00 00 00 02 39 00
15 01 00 00 00 00 02 3A 4B
15 01 00 00 00 00 02 3B 00
15 01 00 00 00 00 02 3D 00
15 01 00 00 00 00 02 3F 00
15 01 00 00 00 00 02 40 00
15 01 00 00 00 00 02 41 00
15 01 00 00 00 00 02 42 00
15 01 00 00 00 00 02 54 03
15 01 00 00 00 00 02 55 77
15 01 00 00 00 00 02 56 F8
15 01 00 00 00 00 02 58 F8
15 01 00 00 00 00 02 59 77
15 01 00 00 00 00 02 5A F8
15 01 00 00 00 00 02 5B F8
15 01 00 00 00 00 02 5C 77
15 01 00 00 00 00 02 5D F8
15 01 00 00 00 00 02 5E F8
15 01 00 00 00 00 02 5F 77
15 01 00 00 00 00 02 60 F8
15 01 00 00 00 00 02 61 F8
15 01 00 00 00 00 02 62 77
15 01 00 00 00 00 02 63 F8
15 01 00 00 00 00 02 64 F8
15 01 00 00 00 00 02 65 77
15 01 00 00 00 00 02 66 F8
15 01 00 00 00 00 02 67 F8
15 01 00 00 00 00 02 77 07
15 01 00 00 00 00 02 78 F8
/* FDC */
15 01 00 00 00 00 02 FE 00
15 01 00 00 00 00 02 2F 05
15 01 00 00 00 00 02 FE 5A
15 01 00 00 00 00 02 4A 1A
15 01 00 00 00 00 02 4B 00
15 01 00 00 00 00 02 52 06
15 01 00 00 00 00 02 53 08
15 01 00 00 00 00 02 55 00
15 01 00 00 00 00 02 5E 00
15 01 00 00 00 00 02 60 00
15 01 00 00 00 00 02 61 00
15 01 00 00 00 00 02 66 00
15 01 00 00 00 00 02 69 00
15 01 00 00 00 00 02 6E 00
15 01 00 00 00 00 02 70 00
15 01 00 00 00 00 02 76 00
15 01 00 00 00 00 02 78 00
15 01 00 00 00 00 02 7E 00
15 01 00 00 00 00 02 86 00
15 01 00 00 00 00 02 91 12
15 01 00 00 00 00 02 92 0A
15 01 00 00 00 00 02 93 10
15 01 00 00 00 00 02 94 06
15 01 00 00 00 00 02 98 10
15 01 00 00 00 00 02 99 00
15 01 00 00 00 00 02 9B 06
15 01 00 00 00 00 02 9C 00
15 01 00 00 00 00 02 A2 00
15 01 00 00 00 00 02 A7 00
15 01 00 00 00 00 02 AA 00
15 01 00 00 00 00 02 AB 00
15 01 00 00 00 00 02 B0 00
15 01 00 00 00 00 02 B3 00
15 01 00 00 00 00 02 B8 00
15 01 00 00 00 00 02 BA 00
15 01 00 00 00 00 02 C0 00
15 01 00 00 00 00 02 C8 00
15 01 00 00 00 00 02 D0 00
15 01 00 00 00 00 02 DB 66
15 01 00 00 00 00 02 DC 5A
15 01 00 00 00 00 02 DD 40
15 01 00 00 00 00 02 DE 30
15 01 00 00 00 00 02 E2 55
15 01 00 00 00 00 02 E3 3C
15 01 00 00 00 00 02 E4 36
15 01 00 00 00 00 02 E5 10
15 01 00 00 00 00 02 E6 00
15 01 00 00 00 00 02 EA 20
15 01 00 00 00 00 02 EB 1E
15 01 00 00 00 00 02 F0 00
15 01 00 00 00 00 02 F3 15
15 01 00 00 00 00 02 F4 16
15 01 00 00 00 00 02 F9 00
15 01 00 00 00 00 02 FE 5B
15 01 00 00 00 00 02 01 12
15 01 00 00 00 00 02 02 12
15 01 00 00 00 00 02 07 00
15 01 00 00 00 00 02 09 0D
15 01 00 00 00 00 02 0F 00
15 01 00 00 00 00 02 11 0A
15 01 00 00 00 00 02 19 06
15 01 00 00 00 00 02 36 10
15 01 00 00 00 00 02 37 00
15 01 00 00 00 00 02 3F 00
15 01 00 00 00 00 02 45 FE
15 01 00 00 00 00 02 46 00
15 01 00 00 00 00 02 47 00
15 01 00 00 00 00 02 4D FA
15 01 00 00 00 00 02 55 00
15 01 00 00 00 00 02 56 00
15 01 00 00 00 00 02 5E 00
					/* init code */
					15 01 00 00 00 00 02 FE 00
					15 01 00 00 00 00 02 C2 08
					15 01 00 00 00 00 02 35 00
					15 01 00 00 00 00 02 53 20
					39 01 00 00 00 00 03 51 00 00
					05 01 00 00 64 00 01 11
					05 01 00 00 14 00 01 29
					];
				qcom,mdss-dsi-off-command = [
					15 01 00 00 14 00 02 FE 00
					05 01 00 00 10 00 01 28
					05 01 00 00 78 00 01 10
				];
				qcom,mdss-dsi-on-command-state = "dsi_lp_mode";
				qcom,mdss-dsi-off-command-state = "dsi_lp_mode";

				qcom,mdss-dsi-lp1-command = [
					15 01 00 00 00 00 02 FE 00
					05 01 00 00 14 00 01 39
				];
				qcom,mdss-dsi-lp1-command-state =
					"dsi_lp_mode";
				qcom,mdss-dsi-nolp-command = [
					15 01 00 00 00 00 02 FE 00
					39 01 00 00 00 00 03 51 00 00
					05 01 00 00 00 00 01 38
				];
				qcom,mdss-dsi-nolp-command-state =
					"dsi_lp_mode";
				qcom,mdss-dsi-timing-switch-command = [
					39 00 00 40 00 00 02 FE 00
					39 00 00 40 00 00 02 2F 05
39 00 00 40 00 00 02 FE 5A
39 00 00 40 00 00 02 4A 1A
39 00 00 40 00 00 02 4B 00
39 00 00 40 00 00 02 52 06
39 00 00 40 00 00 02 53 08
39 00 00 40 00 00 02 55 00
39 00 00 40 00 00 02 5E 00
39 00 00 40 00 00 02 60 00
39 00 00 40 00 00 02 61 00
39 00 00 40 00 00 02 66 00
39 00 00 40 00 00 02 69 00
39 00 00 40 00 00 02 6E 00
39 00 00 40 00 00 02 70 00
39 00 00 40 00 00 02 76 00
39 00 00 40 00 00 02 78 00
39 00 00 40 00 00 02 7E 00
39 00 00 40 00 00 02 86 00
39 00 00 40 00 00 02 91 12
39 00 00 40 00 00 02 92 0A
39 00 00 40 00 00 02 93 10
39 00 00 40 00 00 02 94 06
39 00 00 40 00 00 02 98 10
39 00 00 40 00 00 02 99 00
39 00 00 40 00 00 02 9B 06
39 00 00 40 00 00 02 9C 00
39 00 00 40 00 00 02 A2 00
39 00 00 40 00 00 02 A7 00
39 00 00 40 00 00 02 AA 00
39 00 00 40 00 00 02 AB 00
39 00 00 40 00 00 02 B0 00
39 00 00 40 00 00 02 B3 00
39 00 00 40 00 00 02 B8 00
39 00 00 40 00 00 02 BA 00
39 00 00 40 00 00 02 C0 00
39 00 00 40 00 00 02 C8 00
39 00 00 40 00 00 02 D0 00
39 00 00 40 00 00 02 DB 66
39 00 00 40 00 00 02 DC 5A
39 00 00 40 00 00 02 DD 40
39 00 00 40 00 00 02 DE 30
39 00 00 40 00 00 02 E2 55
39 00 00 40 00 00 02 E3 3C
39 00 00 40 00 00 02 E4 36
39 00 00 40 00 00 02 E5 10
39 00 00 40 00 00 02 E6 00
39 00 00 40 00 00 02 EA 20
39 00 00 40 00 00 02 EB 1E
39 00 00 40 00 00 02 F0 00
39 00 00 40 00 00 02 F3 15
39 00 00 40 00 00 02 F4 16
39 00 00 40 00 00 02 F9 00
39 00 00 40 00 00 02 FE 5B
39 00 00 40 00 00 02 01 12
39 00 00 40 00 00 02 02 12
39 00 00 40 00 00 02 07 00
39 00 00 40 00 00 02 09 0D
39 00 00 40 00 00 02 0F 00
39 00 00 40 00 00 02 11 0A
39 00 00 40 00 00 02 19 06
39 00 00 40 00 00 02 36 10
39 00 00 40 00 00 02 37 00
39 00 00 40 00 00 02 3F 00
39 00 00 40 00 00 02 45 FE
39 00 00 40 00 00 02 46 00
39 00 00 40 00 00 02 47 00
39 00 00 40 00 00 02 4D FA
39 00 00 40 00 00 02 55 00
39 00 00 40 00 00 02 56 00
39 00 00 40 00 00 02 5E 00
					39 00 00 00 00 00 02 FE 00
				];
				qcom,mdss-dsi-timing-switch-command-state =
				"dsi_lp_mode";
				qcom,compression-mode = "dsc";
				qcom,mdss-dsc-slice-height = <16>;
				qcom,mdss-dsc-slice-width = <608>;
				qcom,mdss-dsc-slice-per-pkt = <2>;
				qcom,mdss-dsc-bit-per-component = <10>;
				qcom,mdss-dsc-bit-per-pixel = <8>;
				qcom,mdss-dsc-block-prediction-enable;
			};
			timing@3{
				cell-index = <3>;
				qcom,mdss-dsi-panel-width = <1216>;
				qcom,mdss-dsi-panel-height = <2688>;
				qcom,mdss-dsi-h-front-porch = <8>;
				qcom,mdss-dsi-h-back-porch = <12>;
				qcom,mdss-dsi-h-pulse-width = <8>;
				qcom,mdss-dsi-h-sync-skew = <0>;
				qcom,mdss-dsi-v-back-porch = <8>;
				qcom,mdss-dsi-v-front-porch = <56>;
				qcom,mdss-dsi-v-pulse-width = <8>;
				qcom,mdss-dsi-h-sync-pulse = <0>;
				qcom,mdss-dsi-h-left-border = <0>;
				qcom,mdss-dsi-h-right-border = <0>;
				qcom,mdss-dsi-v-top-border = <0>;
				qcom,mdss-dsi-v-bottom-border = <0>;
				qcom,mdss-dsi-panel-framerate = <144>;
				qcom,mdss-mdp-transfer-time-us = <6235>;
				/*qcom,mdss-dsi-panel-clockrate = <1060474224>;*/
				/*qcom,mdss-dsi-panel-clockrate = <1052220000>; 144HZ*/

				qcom,mdss-dsi-on-command = [
					/* ESD RECOVER */
					15 01 00 00 00 00 02 FE D4
					15 01 00 00 00 00 02 40 03
					15 01 00 00 00 00 02 FE FD
					15 01 00 00 00 00 02 80 06
					15 01 00 00 00 00 02 83 00
					15 01 00 00 00 00 02 EE 00
					15 01 00 00 00 00 02 EF 00
					15 01 00 00 00 00 02 FE D0
					15 01 00 00 00 00 02 7E 80
					15 01 00 00 00 00 02 FE B6
					15 01 00 00 00 00 02 01 74
					15 01 00 00 00 00 02 FE A1
					15 01 00 00 00 00 02 74 72
					15 01 00 00 00 00 02 C3 C3
					15 01 00 00 00 00 02 C4 FF
					15 01 00 00 00 00 02 C5 7F
/*10bit 3.75 begin*/
15 01 00 00 00 00 02 FE 00
15 01 00 00 00 00 02 FA 01
15 01 00 00 00 00 02 FE D2
15 01 00 00 00 00 02 97 08
15 01 00 00 00 00 02 36 11
15 01 00 00 00 00 02 39 ab
15 01 00 00 00 00 02 3A 30
15 01 00 00 00 00 02 3B 80
15 01 00 00 00 00 02 3D 0a
15 01 00 00 00 00 02 3F 80
15 01 00 00 00 00 02 40 04
15 01 00 00 00 00 02 41 c0
15 01 00 00 00 00 02 42 00
15 01 00 00 00 00 02 43 10
15 01 00 00 00 00 02 44 02
15 01 00 00 00 00 02 45 60
15 01 00 00 00 00 02 46 02
15 01 00 00 00 00 02 47 60
15 01 00 00 00 00 02 48 02
15 01 00 00 00 00 02 49 00
15 01 00 00 00 00 02 4A 02
15 01 00 00 00 00 02 4B 31
15 01 00 00 00 00 02 4D 20
15 01 00 00 00 00 02 4E 01
15 01 00 00 00 00 02 4F 68
15 01 00 00 00 00 02 50 00
15 01 00 00 00 00 02 51 08
15 01 00 00 00 00 02 53 0c
15 01 00 00 00 00 02 54 06
15 01 00 00 00 00 02 55 67
15 01 00 00 00 00 02 56 05
15 01 00 00 00 00 02 58 ad
15 01 00 00 00 00 02 59 18
15 01 00 00 00 00 02 5A 00
15 01 00 00 00 00 02 5B 11
15 01 00 00 00 00 02 5C 00
15 01 00 00 00 00 02 5D 07
15 01 00 00 00 00 02 5E 10
15 01 00 00 00 00 02 5F 20
15 01 00 00 00 00 02 60 00
15 01 00 00 00 00 02 61 06
15 01 00 00 00 00 02 62 0f
15 01 00 00 00 00 02 63 0f
15 01 00 00 00 00 02 64 33
15 01 00 00 00 00 02 65 0e
15 01 00 00 00 00 02 66 1c
15 01 00 00 00 00 02 67 2a
15 01 00 00 00 00 02 68 38
15 01 00 00 00 00 02 69 46
15 01 00 00 00 00 02 6A 54
15 01 00 00 00 00 02 6B 62
15 01 00 00 00 00 02 6C 69
15 01 00 00 00 00 02 6D 70
15 01 00 00 00 00 02 6E 77
15 01 00 00 00 00 02 6F 79
15 01 00 00 00 00 02 70 7b
15 01 00 00 00 00 02 71 7d
15 01 00 00 00 00 02 72 7e
15 01 00 00 00 00 02 73 02
15 01 00 00 00 00 02 74 02
15 01 00 00 00 00 02 75 22
15 01 00 00 00 00 02 76 00
15 01 00 00 00 00 02 77 2a
15 01 00 00 00 00 02 78 40
15 01 00 00 00 00 02 79 2a
15 01 00 00 00 00 02 7A be
15 01 00 00 00 00 02 7B 3a
15 01 00 00 00 00 02 7C fc
15 01 00 00 00 00 02 7D 3a
15 01 00 00 00 00 02 7E fa
15 01 00 00 00 00 02 7F 3a
15 01 00 00 00 00 02 80 f8
15 01 00 00 00 00 02 81 3b
15 01 00 00 00 00 02 82 38
15 01 00 00 00 00 02 83 3b
15 01 00 00 00 00 02 84 78
15 01 00 00 00 00 02 85 3b
15 01 00 00 00 00 02 86 b6
15 01 00 00 00 00 02 87 4b
15 01 00 00 00 00 02 88 f6
15 01 00 00 00 00 02 89 4c
15 01 00 00 00 00 02 8A 34
15 01 00 00 00 00 02 8B 4c
15 01 00 00 00 00 02 8C 74
15 01 00 00 00 00 02 8D 5c
15 01 00 00 00 00 02 8E 74
15 01 00 00 00 00 02 8F 8c
15 01 00 00 00 00 02 90 f4
15 01 00 00 00 00 02 91 00
15 01 00 00 00 00 02 92 00
15 01 00 00 00 00 02 93 00
15 01 00 00 00 00 02 94 00
15 01 00 00 00 00 02 95 00
15 01 00 00 00 00 02 96 00
/*10bit 3.75 end*/
/*acl function*/
15 01 00 00 00 00 02 FE 34
15 01 00 00 00 00 02 82 C0
15 01 00 00 00 00 02 83 04
15 01 00 00 00 00 02 00 08
15 01 00 00 00 00 02 1C 00
15 01 00 00 00 00 02 1D 10
15 01 00 00 00 00 02 49 05
15 01 00 00 00 00 02 1E 00
15 01 00 00 00 00 02 1F 00
15 01 00 00 00 00 02 20 00
15 01 00 00 00 00 02 21 70
15 01 00 00 00 00 02 22 00
15 01 00 00 00 00 02 23 F8
15 01 00 00 00 00 02 24 77
15 01 00 00 00 00 02 25 F8
15 01 00 00 00 00 02 26 F8
15 01 00 00 00 00 02 2F 00
15 01 00 00 00 00 02 30 00
15 01 00 00 00 00 02 31 00
15 01 00 00 00 00 02 32 00
15 01 00 00 00 00 02 33 00
15 01 00 00 00 00 02 34 00
15 01 00 00 00 00 02 35 00
15 01 00 00 00 00 02 36 C4
15 01 00 00 00 00 02 37 00
15 01 00 00 00 00 02 38 87
15 01 00 00 00 00 02 39 00
15 01 00 00 00 00 02 3A 4B
15 01 00 00 00 00 02 3B 00
15 01 00 00 00 00 02 3D 00
15 01 00 00 00 00 02 3F 00
15 01 00 00 00 00 02 40 00
15 01 00 00 00 00 02 41 00
15 01 00 00 00 00 02 42 00
15 01 00 00 00 00 02 54 03
15 01 00 00 00 00 02 55 77
15 01 00 00 00 00 02 56 F8
15 01 00 00 00 00 02 58 F8
15 01 00 00 00 00 02 59 77
15 01 00 00 00 00 02 5A F8
15 01 00 00 00 00 02 5B F8
15 01 00 00 00 00 02 5C 77
15 01 00 00 00 00 02 5D F8
15 01 00 00 00 00 02 5E F8
15 01 00 00 00 00 02 5F 77
15 01 00 00 00 00 02 60 F8
15 01 00 00 00 00 02 61 F8
15 01 00 00 00 00 02 62 77
15 01 00 00 00 00 02 63 F8
15 01 00 00 00 00 02 64 F8
15 01 00 00 00 00 02 65 77
15 01 00 00 00 00 02 66 F8
15 01 00 00 00 00 02 67 F8
15 01 00 00 00 00 02 77 07
15 01 00 00 00 00 02 78 F8
/* FDC */
15 01 00 00 00 00 02 FE 00
15 01 00 00 00 00 02 2F 00
15 01 00 00 00 00 02 FE 5A
15 01 00 00 00 00 02 4A 1A
15 01 00 00 00 00 02 52 06
15 01 00 00 00 00 02 53 08
15 01 00 00 00 00 02 60 00
15 01 00 00 00 00 02 61 00
15 01 00 00 00 00 02 66 00
15 01 00 00 00 00 02 6E 00
15 01 00 00 00 00 02 70 00
15 01 00 00 00 00 02 76 00
15 01 00 00 00 00 02 7E 00
15 01 00 00 00 00 02 86 00
15 01 00 00 00 00 02 91 12
15 01 00 00 00 00 02 92 0A
15 01 00 00 00 00 02 93 10
15 01 00 00 00 00 02 94 06
15 01 00 00 00 00 02 98 10
15 01 00 00 00 00 02 99 00
15 01 00 00 00 00 02 9B 06
15 01 00 00 00 00 02 B0 00
15 01 00 00 00 00 02 B8 00
15 01 00 00 00 00 02 C0 00
15 01 00 00 00 00 02 C8 00
15 01 00 00 00 00 02 D0 00
15 01 00 00 00 00 02 DB 66
15 01 00 00 00 00 02 DC 5A
15 01 00 00 00 00 02 DD 40
15 01 00 00 00 00 02 DE 30
15 01 00 00 00 00 02 E2 55
15 01 00 00 00 00 02 E3 30
15 01 00 00 00 00 02 E4 36
15 01 00 00 00 00 02 E5 10
15 01 00 00 00 00 02 EA 20
15 01 00 00 00 00 02 EB 1E
15 01 00 00 00 00 02 F3 15
15 01 00 00 00 00 02 F4 16
15 01 00 00 00 00 02 F9 00
15 01 00 00 00 00 02 FE 5B
15 01 00 00 00 00 02 01 12
15 01 00 00 00 00 02 02 12
15 01 00 00 00 00 02 07 00
15 01 00 00 00 00 02 09 00
15 01 00 00 00 00 02 0F 00
15 01 00 00 00 00 02 11 0A
15 01 00 00 00 00 02 19 06
15 01 00 00 00 00 02 36 10
15 01 00 00 00 00 02 37 00
15 01 00 00 00 00 02 3F 10
15 01 00 00 00 00 02 45 FE
15 01 00 00 00 00 02 46 10
15 01 00 00 00 00 02 47 10
15 01 00 00 00 00 02 4D FA
15 01 00 00 00 00 02 55 00
15 01 00 00 00 00 02 56 00
15 01 00 00 00 00 02 5E 00
					/*init code*/
					15 01 00 00 00 00 02 FE 00
					15 01 00 00 00 00 02 C2 08
					15 01 00 00 00 00 02 35 00
					15 01 00 00 00 00 02 53 20
					39 01 00 00 00 00 03 51 00 00
					05 01 00 00 64 00 01 11
					05 01 00 00 14 00 01 29
					];
				qcom,mdss-dsi-off-command = [
					15 01 00 00 14 00 02 FE 00
					05 01 00 00 10 00 01 28
					05 01 00 00 78 00 01 10
				];
				qcom,mdss-dsi-on-command-state = "dsi_lp_mode";
				qcom,mdss-dsi-off-command-state = "dsi_lp_mode";

				qcom,mdss-dsi-lp1-command = [
					15 01 00 00 00 00 02 FE 00
					05 01 00 00 14 00 01 39
				];
				qcom,mdss-dsi-lp1-command-state =
					"dsi_lp_mode";
				qcom,mdss-dsi-nolp-command = [
					15 01 00 00 00 00 02 FE 00
					39 01 00 00 00 00 03 51 00 00
					05 01 00 00 00 00 01 38
				];
				qcom,mdss-dsi-nolp-command-state =
					"dsi_lp_mode";
				qcom,mdss-dsi-timing-switch-command = [
39 00 00 40 00 00 02 FE 00
39 00 00 40 00 00 02 2F 00

39 00 00 40 00 00 02 FE 5A
39 00 00 40 00 00 02 4A 1A
39 00 00 40 00 00 02 52 06
39 00 00 40 00 00 02 53 08
39 00 00 40 00 00 02 60 00
39 00 00 40 00 00 02 61 00
39 00 00 40 00 00 02 66 00
39 00 00 40 00 00 02 6E 00
39 00 00 40 00 00 02 70 00
39 00 00 40 00 00 02 76 00
39 00 00 40 00 00 02 7E 00
39 00 00 40 00 00 02 86 00
39 00 00 40 00 00 02 91 12
39 00 00 40 00 00 02 92 0A
39 00 00 40 00 00 02 93 10
39 00 00 40 00 00 02 94 06
39 00 00 40 00 00 02 98 10
39 00 00 40 00 00 02 99 00
39 00 00 40 00 00 02 9B 06
39 00 00 40 00 00 02 B0 00
39 00 00 40 00 00 02 B8 00
39 00 00 40 00 00 02 C0 00
39 00 00 40 00 00 02 C8 00
39 00 00 40 00 00 02 D0 00
39 00 00 40 00 00 02 DB 66
39 00 00 40 00 00 02 DC 5A
39 00 00 40 00 00 02 DD 40
39 00 00 40 00 00 02 DE 30
39 00 00 40 00 00 02 E2 55
39 00 00 40 00 00 02 E3 30
39 00 00 40 00 00 02 E4 36
39 00 00 40 00 00 02 E5 10
39 00 00 40 00 00 02 EA 20
39 00 00 40 00 00 02 EB 1E
39 00 00 40 00 00 02 F3 15
39 00 00 40 00 00 02 F4 16
39 00 00 40 00 00 02 F9 00
39 00 00 40 00 00 02 FE 5B
39 00 00 40 00 00 02 01 12
39 00 00 40 00 00 02 02 12
39 00 00 40 00 00 02 07 00
39 00 00 40 00 00 02 09 00
39 00 00 40 00 00 02 0F 00
39 00 00 40 00 00 02 11 0A
39 00 00 40 00 00 02 19 06
39 00 00 40 00 00 02 36 10
39 00 00 40 00 00 02 37 00
39 00 00 40 00 00 02 3F 10
39 00 00 40 00 00 02 45 FE
39 00 00 40 00 00 02 46 10
39 00 00 40 00 00 02 47 10
39 00 00 40 00 00 02 4D FA
39 00 00 40 00 00 02 55 00
39 00 00 40 00 00 02 56 00
39 00 00 40 00 00 02 5E 00
					39 00 00 00 00 00 02 FE 00
				];
				qcom,mdss-dsi-timing-switch-command-state =
				"dsi_lp_mode";
				qcom,compression-mode = "dsc";
				qcom,mdss-dsc-slice-height = <16>;
				qcom,mdss-dsc-slice-width = <608>;
				qcom,mdss-dsc-slice-per-pkt = <2>;
				qcom,mdss-dsc-bit-per-component = <10>;
				qcom,mdss-dsc-bit-per-pixel = <8>;
				qcom,mdss-dsc-block-prediction-enable;
			};
		};
	};
};

/* panel feature */
&dsi_bf237_rm692h5_6p8_dev0_dsc_cmd {
    /* zte disp feature */
	zte,hbm_enabled;
	zte,fps_enabled;
	zte,aod_enabled;
	zte,acl_enabled;
	zte,color_space_enabled;
	zte,bl_limit_enabled;
	zte,te-high-width = <8500>;
	qcom,mdss-dsi-display-timings {
		timing@0 {
		   #include "dsi-panel-zte-bf237-rm692h5-6p8-common.dtsi"
		};
		timing@1 {
		   #include "dsi-panel-zte-bf237-rm692h5-6p8-common.dtsi"
		};
		timing@2 {
		   #include "dsi-panel-zte-bf237-rm692h5-6p8-common.dtsi"
		};
		timing@3 {
		   #include "dsi-panel-zte-bf237-rm692h5-6p8-common.dtsi"
		};
	};
};

/* zte dsip power supply */
&dsi_bf237_rm692h5_6p8_dev0_dsc_cmd {
	qcom,panel-supply-entries = <&dsi_panel_pwr_supply>;
	qcom,mdss-dsi-bl-pmic-control-type = "bl_ctrl_dcs";
	qcom,mdss-brightness-max-level = <2047>;
	qcom,mdss-dsi-bl-inverted-dbv;
	qcom,platform-reset-gpio = <&tlmm 98 0>;
	qcom,ulps-enabled;
	qcom,esd-check-enabled;
	qcom,mdss-dsi-panel-status-check-mode = "reg_read";
	qcom,mdss-dsi-panel-status-command = [
		06 01 00 01 05 00 01 0A
		06 01 00 01 05 00 01 FA
		06 01 00 01 05 00 01 0B];
	qcom,mdss-dsi-panel-status-command-state = "dsi_lp_mode";
	qcom,mdss-dsi-panel-status-value = <0x9c 0x01 0x00>;
	qcom,mdss-dsi-panel-status-read-length = <1 1 1>;
	qcom,dsi-select-clocks = "pll_byte_clk0", "pll_dsi_clk0";
	qcom,mdss-dsi-display-timings {
		timing@0 { /* 60Hz */
			/* DPHY regular margins */
			qcom,mdss-dsi-panel-phy-timings = [00 23 09 09 1A 24
				09 09 09 02 04 00 1D 0E];
			qcom,display-topology = <2 2 1>;
			qcom,default-topology-index = <0>;
		};
		timing@1 { /* 90Hz */
			/* DPHY regular margins */
			qcom,mdss-dsi-panel-phy-timings = [00 23 09 09 1A 24
				09 09 09 02 04 00 1D 0E];
			qcom,display-topology = <2 2 1>;
			qcom,default-topology-index = <0>;
		};
		timing@2 { /* 120Hz */
			/* DPHY regular margins */
			qcom,mdss-dsi-panel-phy-timings = [00 23 09 09 1A 18
				09 09 09 02 04 00 1D 0E];
			qcom,display-topology = <2 2 1>;
			qcom,default-topology-index = <0>;
		};
		timing@3 { /* 144Hz */
			/* DPHY regular margins */
			qcom,mdss-dsi-panel-phy-timings = [00 23 09 09 1A 18
				09 09 09 02 04 00 1D 0E];
			qcom,display-topology = <2 2 1>;
			qcom,default-topology-index = <0>;
		};
	};
};
